# MKM34Z7 register map
Vendor: Freescale Semiconductor, Inc.; Series: Kinetis_M; File version: 1.6
CPU: CM0PLUS r0p0, little endian, no MPU, no FPU, VTOR, 2 interrupt priority bits
Registers are 8-bit, read-write, reset 0x0 unless marked. A register's access mark holds for its fields unless they carry their own. Offsets are from the block's base; [hi:lo] are bit positions; {n}, {i} and the like mark numbered series; 'fields as' and 'values as' point back to an identical list.

## AFE — This section describes the ADC registers.
Base 0x40030000; register names take the prefix AFE_
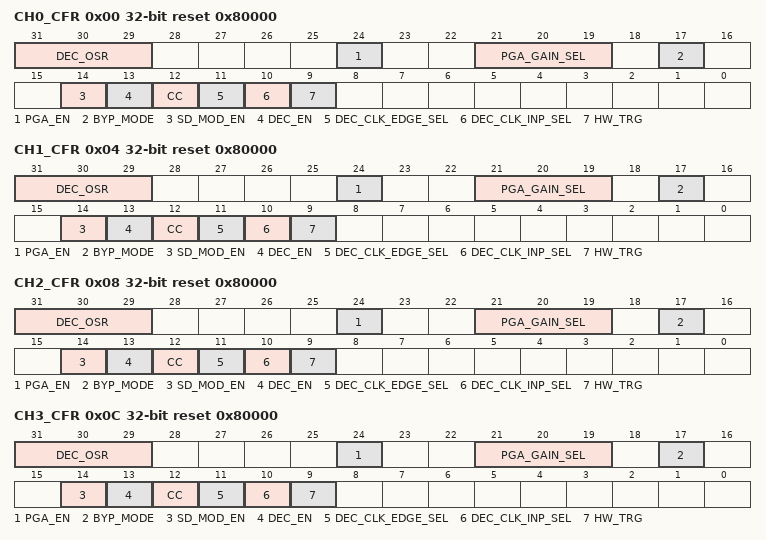
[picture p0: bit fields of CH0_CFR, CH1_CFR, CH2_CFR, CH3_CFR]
0x00 CH0_CFR 32-bit reset 0x80000 — Channel0 Configuration Register
  [31:29] DEC_OSR — Decimator OverSampling Ratio select
    0=64; 1=128; 2=256; 3=512; 4=1024; 5=2048
  [24] PGA_EN — PGA enable
    0=PGA disabled; 1=PGA enabled
  [21:19] PGA_GAIN_SEL — PGA Gain Select
    1=1x (default); 2=2x; 3=4x; 4=8x; 5=16x; 6=32x
  [17] BYP_MODE — AFE Channel0 bypass mode
    0=Normal mode; 1=Bypass mode where ADC and PGA of channel0 are disabled
  [14] SD_MOD_EN — Sigma Delta Modulator enable
    0=SD ADC1 is disabled; 1=SD ADC1 is enabled
  [13] DEC_EN — Decimation Filter enable
    0=Decimation filter is disabled; 1=Decimation filter is enabled
  [12] CC — Continuous Conversion/Single Conversion Mode Select
    0=One conversion following a triggering event; 1=Continuous conversions following a triggering event
  [11] DEC_CLK_EDGE_SEL — Decimator Clock Edge Select
    0=Posedge will be used; 1=Negedge will be used
  [10] DEC_CLK_INP_SEL — Decimator Clock Input Select
    0=On the chip modulator clock will be used; 1=External clock will be used
  [9] HW_TRG — Hardware Trigger Select
    0=Software trigger select; 1=Hardware trigger select
0x04 CH1_CFR 32-bit reset 0x80000 — Channel1 Configuration Register
  [31:29] DEC_OSR — Decimator OverSampling Ratio select
    0=64; 1=128; 2=256; 3=512; 4=1024; 5=2048
  [24] PGA_EN — PGA enable
    0=PGA disabled; 1=PGA enabled
  [21:19] PGA_GAIN_SEL — PGA Gain Select
    1=1x (default); 2=2x; 3=4x; 4=8x; 5=16x; 6=32x
  [17] BYP_MODE — AFE Channel1 bypass mode
    0=Normal mode; 1=Bypass mode where ADC and PGA of channel1 are disabled
  [14] SD_MOD_EN — Sigma Delta Modulator enable
    0=SD ADC1 is disabled; 1=SD ADC1 is enabled
  [13] DEC_EN — Decimation Filter enable
    values as CH0_CFR.DEC_EN
  [12] CC — Continuous Conversion/Single Conversion Mode Select
    values as CH0_CFR.CC
  [11] DEC_CLK_EDGE_SEL — Decimator Clock Edge Select
    0=Posedge will be used; 1=Negedge will be used
  [10] DEC_CLK_INP_SEL — Decimator Clock Input Select
    values as CH0_CFR.DEC_CLK_INP_SEL
  [9] HW_TRG — Hardware Trigger Select
    0=Software trigger select; 1=Hardware trigger select
0x08 CH2_CFR 32-bit reset 0x80000 — Channel2 Configuration Register
  [31:29] DEC_OSR — Decimator OverSampling Ratio select
    0=64; 1=128; 2=256; 3=512; 4=1024; 5=2048
  [24] PGA_EN — It enables the PGA gain stage.
    0=PGA disabled; 1=PGA enabled
  [21:19] PGA_GAIN_SEL — This field selects the analog gain applied to the input signal.
    1=1x(default); 2=2x; 3=4x; 4=8x; 5=16x; 6=32x
  [17] BYP_MODE — AFE Channel2 bypass mode
    0=Normal mode; 1=Bypass mode where ADC and PGA of channel2 are disabled
  [14] SD_MOD_EN — Sigma Delta Modulator enable
    0=SD ADC3 is disabled; 1=SD ADC3 is enabled
  [13] DEC_EN — Decimation Filter enable
    values as CH0_CFR.DEC_EN
  [12] CC — Continuous Conversion/Single Conversion Mode Select
    values as CH0_CFR.CC
  [11] DEC_CLK_EDGE_SEL — Decimator Clock Edge Select
    0=Posedge will be used; 1=Negedge will be used
  [10] DEC_CLK_INP_SEL — Decimator Clock Input Select
    values as CH0_CFR.DEC_CLK_INP_SEL
  [9] HW_TRG — Hardware Trigger Select
    0=Software trigger select; 1=Hardware trigger select
0x0C CH3_CFR 32-bit reset 0x80000 — Channel3 Configuration Register
  [31:29] DEC_OSR — Decimator OverSampling Ratio select
    0=64; 1=128; 2=256; 3=512; 4=1024; 5=2048
  [24] PGA_EN — It enables the PGA gain stage.
    0=PGA disabled; 1=PGA enabled
  [21:19] PGA_GAIN_SEL — This field selects the analog gain applied to the input signal.
    1=1x(default); 2=2x; 3=4x; 4=8x; 5=16x; 6=32x
  [17] BYP_MODE — AFE Channel3 bypass mode
    0=Normal mode; 1=Bypass mode where ADC and PGA of channel3 are disabled
  [14] SD_MOD_EN — Sigma Delta Modulator enable
    0=SD ADC3 is disabled; 1=SD ADC3 is enabled
  [13] DEC_EN — Decimation Filter enable
    values as CH0_CFR.DEC_EN
  [12] CC — Continuous Conversion/Single Conversion Mode Select
    values as CH0_CFR.CC
  [11] DEC_CLK_EDGE_SEL — Decimator Clock Edge Select
    0=Posedge will be used; 1=Negedge will be used
  [10] DEC_CLK_INP_SEL — Decimator Clock Input Select
    values as CH0_CFR.DEC_CLK_INP_SEL
  [9] HW_TRG — Hardware Trigger Select
    0=Software trigger select; 1=Hardware trigger select
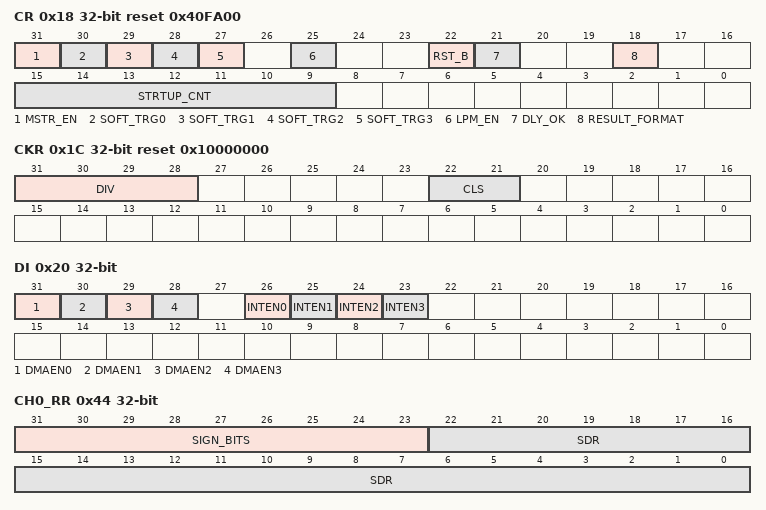
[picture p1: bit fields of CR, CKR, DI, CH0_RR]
0x18 CR 32-bit reset 0x40FA00 — Control Register
  [31] MSTR_EN — AFE Master Enable
    0=All ADCs are disabled; 1=All ADCs and filters will get simultaneously enabled 
  [30-n] SOFT_TRG{n} wo (n=0..3) — Software Trigger{n}
  [25] LPM_EN — Low power Mode enable
    0=AFE will be in normal mode; 1=AFE will be in low power mode. Setting this bit reduce the current consumption of ADC and Buffer Amplifier , the max modulator clock frequency is below 1Mhz.
  [22] RST_B — Software Reset
    0=All ADCs, PGAs and Decimation filters are disabled. Clock Configuration bits will be reset.; 1=.= All ADCs, PGAs and Decimation filters are enabled
  [21] DLY_OK wo — Delay OK
  [18] RESULT_FORMAT
    0=Left justified 2's complement 32-bit : SVVVVVVVVVVVVVVVVVVVVVVV00000000 where (S= sign bit , V=valid result value, 0=zero); 1=Right justified 2's complement 32-bit : SSSSSSSSSVVVVVVVVVVVVVVVVVVVVVVV where (S= sign bit , V= valid result value, 0= zero)
  [15:9] STRTUP_CNT — Start up count
0x1C CKR 32-bit reset 0x10000000 — Clock Configuration Register
  [31:28] DIV — Clock Divider Select
    0=divide by 1; 1=divide by 2 (default); 2=divide by 4; 3=divide by 8; 4=divide by 16; 5=divide by 32; 6=divide by 64; 7=divide by 128; 0b1xxx=divide by 256
  [22:21] CLS — Clock Source Select
    {v}=mod_clk{v} (v=0..3)
0x20 DI 32-bit — DMA and Interrupt Register
  [31-n] DMAEN{n} (n=0..3) — DMA Enable{n}
  [26-n] INTEN{n} (n=0..3) — Interrupt Enable {n}
{0x2C+4i} CH{i}_DR 32-bit (i=0..3) — Channel{i} Delay Register
  [10:0] DLY — Delay
0x44 CH0_RR 32-bit ro — Channel0 Result Register
  [31:23] SIGN_BITS
  [22:0] SDR — Sample Data Result
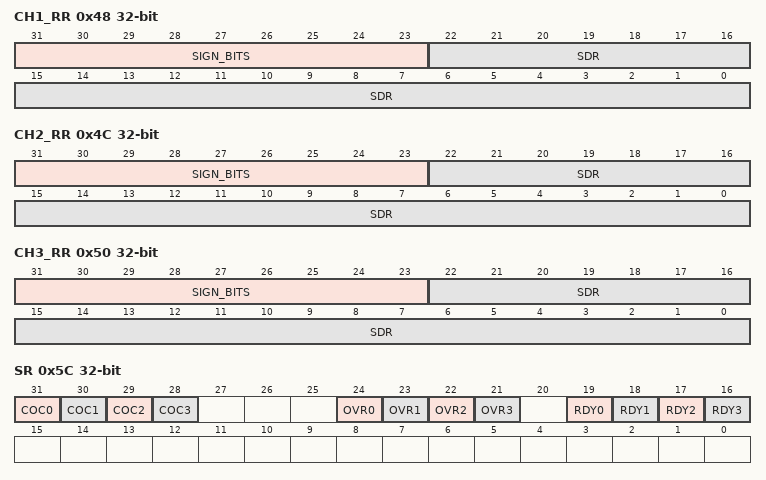
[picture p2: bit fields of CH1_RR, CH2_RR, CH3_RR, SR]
0x48 CH1_RR 32-bit ro — Channel1 Result Register
  [31:23] SIGN_BITS
  [22:0] SDR — Sample Data Result
0x4C CH2_RR 32-bit ro — Channel2 Result Register
  [31:23] SIGN_BITS
  [22:0] SDR — Sample Data result
0x50 CH3_RR 32-bit ro — Channel3 Result Register
  [31:23] SIGN_BITS
  [22:0] SDR — Sample Data result
0x5C SR 32-bit ro — Status Register
  [31-n] COC{n} (n=0..3) — Conversion Complete
  [24-n] OVR{n} (n=0..3) — Overflow Flag
  [19-n] RDY{n} (n=0..3) — AFE Ready{n}
    0=AFE Channel{n} is disabled or has not completed its start up period; 1=AFE Channel{n} is ready to initiate conversions

## Notices in the file
Redistribution and use in source and binary forms, with or without modification,
are permitted provided that the following conditions are met:
o Redistributions of source code must retain the above copyright notice, this list
of conditions and the following disclaimer.
o Redistributions in binary form must reproduce the above copyright notice, this
list of conditions and the following disclaimer in the documentation and/or
other materials provided with the distribution.
o Neither the name of Freescale Semiconductor, Inc. nor the names of its
contributors may be used to endorse or promote products derived from this
software without specific prior written permission.
THIS SOFTWARE IS PROVIDED BY THE COPYRIGHT HOLDERS AND CONTRIBUTORS "AS IS" AND
ANY EXPRESS OR IMPLIED WARRANTIES, INCLUDING, BUT NOT LIMITED TO, THE IMPLIED
WARRANTIES OF MERCHANTABILITY AND FITNESS FOR A PARTICULAR PURPOSE ARE
DISCLAIMED. IN NO EVENT SHALL THE COPYRIGHT HOLDER OR CONTRIBUTORS BE LIABLE FOR
ANY DIRECT, INDIRECT, INCIDENTAL, SPECIAL, EXEMPLARY, OR CONSEQUENTIAL DAMAGES
(INCLUDING, BUT NOT LIMITED TO, PROCUREMENT OF SUBSTITUTE GOODS OR SERVICES;
LOSS OF USE, DATA, OR PROFITS; OR BUSINESS INTERRUPTION) HOWEVER CAUSED AND ON
ANY THEORY OF LIABILITY, WHETHER IN CONTRACT, STRICT LIABILITY, OR TORT
(INCLUDING NEGLIGENCE OR OTHERWISE) ARISING IN ANY WAY OUT OF THE USE OF THIS
SOFTWARE, EVEN IF ADVISED OF THE POSSIBILITY OF SUCH DAMAGE.
